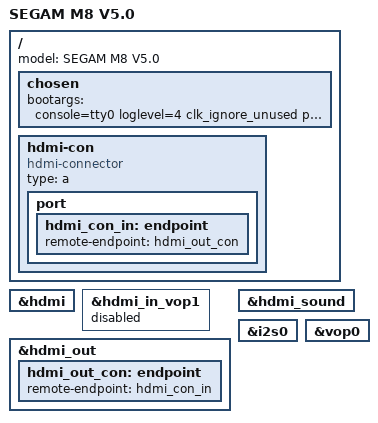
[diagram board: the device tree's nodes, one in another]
// SPDX-License-Identifier: (GPL-2.0+ OR MIT)
/* Full version: both CPUs, display driver (VOP0 + HDMI, 1280x720, page flipping), HDMI audio.
 * Until the display driver starts, the console is on the stock picture (simplefb). */
/dts-v1/;
#include "rk3066a-segam-m8.dtsi"

/ {
	model = "SEGAM M8 V5.0";

	chosen {
		bootargs = "console=tty0 loglevel=4 clk_ignore_unused pd_ignore_unused regulator_ignore_unused oops=panic panic=120 video=HDMI-A-1:1280x720-16@60 rdinit=/init";
	};

	hdmi-con {
		compatible = "hdmi-connector";
		type = "a";

		port {
			hdmi_con_in: endpoint {
				remote-endpoint = <&hdmi_out_con>;
			};
		};
	};
};

&hdmi {
	status = "okay";
};

&hdmi_in_vop1 {
	status = "disabled";
};

&hdmi_out {
	hdmi_out_con: endpoint {
		remote-endpoint = <&hdmi_con_in>;
	};
};

&hdmi_sound {
	status = "okay";
};

/* HDMI audio: I2S0 is connected to the HDMI block inside the chip, its pins are not used */
&i2s0 {
	/delete-property/ pinctrl-names;
	/delete-property/ pinctrl-0;
	status = "okay";
};

&vop0 {
	status = "okay";
};
